# ATmega32M1 register map
Vendor: Atmel; File version: 1.0
CPU: other r0p0, little endian, no MPU, no FPU, 4 interrupt priority bits
Registers are 8-bit, read-write, reset 0x0 unless marked. A register's access mark holds for its fields unless they carry their own. Offsets are from the block's base; lines under a group give offsets from that group; [hi:lo] are bit positions; {n}, {i} and the like mark numbered series; 'fields as' and 'values as' point back to an identical list; <NAME> marks a mode.

## Memory map
0x00800000 FUSE size 0x3 — Fuses
0x00800000 LOCKBIT size 0x1 — Lockbits
0x00800023 PORTB size 0x3 — I/O Port
0x00800026 PORTC size 0x3 — I/O Port
0x00800029 PORTD size 0x3 — I/O Port
0x0080002C PORTE size 0x3 — I/O Port
0x00800035 TC0 blocks up to offset 0x3A — Timer/Counter, 8-bit
0x00800036 TC1 blocks up to offset 0x56 — Timer/Counter, 16-bit
0x00800039 CPU blocks up to offset 0x2E — CPU Registers
0x0080003B EXINT blocks up to offset 0x33 — External Interrupts
0x0080003F EEPROM size 0x4
0x0080004C SPI size 0x3 — Serial Peripheral Interface
0x00800050 AC blocks up to offset 0x48 — Analog Comparator
0x00800060 WDT size 0x1 — Watchdog Timer
0x00800075 ADC blocks up to offset 0xB — Analog-to-Digital Converter
0x00800090 DAC size 0x3 — Digital-to-Analog Converter
0x008000A0 PSC size 0x1D — Power Stage Controller
0x008000C8 LINUART size 0xB — Local Interconnect Network
0x008000D8 CAN size 0x23 — Controller Area Network

## Interrupts
0 RESET (CPU) — External Pin, Power-on Reset, Brown-out Reset, Watchdog Reset and JTAG AVR Reset
1 ANACOMP0 (CPU) — Analog Comparator 0
2 ANACOMP1 (CPU) — Analog Comparator 1
3 ANACOMP2 (CPU) — Analog Comparator 2
4 ANACOMP3 (CPU) — Analog Comparator 3
5 PSC_FAULT (CPU)
6 PSC_EC (CPU) — PSC End of Cycle
7 INT0 (CPU) — External Interrupt Request 0
8 INT1 (CPU) — External Interrupt Request 1
9 INT2 (CPU) — External Interrupt Request 2
10 INT3 (CPU) — External Interrupt Request 3
11 TIMER1_CAPT (CPU) — Timer/Counter1 Capture Event
12 TIMER1_COMPA (CPU) — Timer/Counter1 Compare Match A
13 TIMER1_COMPB (CPU) — Timer/Counter1 Compare Match B
14 TIMER1_OVF (CPU) — Timer1/Counter1 Overflow
15 TIMER0_COMPA (CPU) — Timer/Counter0 Compare Match A
16 TIMER0_COMPB (CPU) — Timer/Counter0 Compare Match B
17 TIMER0_OVF (CPU) — Timer/Counter0 Overflow
18 CAN_INT (CPU) — CAN MOB, Burst, General Errors
19 CAN_TOVF (CPU) — CAN Timer Overflow
20 LIN_TC (CPU) — LIN Transfer Complete
21 LIN_ERR (CPU) — LIN Error
22 PCINT0 (CPU) — Pin Change Interrupt Request 0
23 PCINT1 (CPU) — Pin Change Interrupt Request 1
24 PCINT2 (CPU) — Pin Change Interrupt Request 2
25 PCINT3 (CPU) — Pin Change Interrupt Request 3
26 SPI_STC (CPU) — SPI Serial Transfer Complete
27 ADC (CPU) — ADC Conversion Complete
28 WDT (CPU) — Watchdog Time-Out Interrupt
29 EE_READY (CPU) — EEPROM Ready
30 SPM_READY (CPU) — Store Program Memory Read

## AC — Analog Comparator
Base 0x00800050
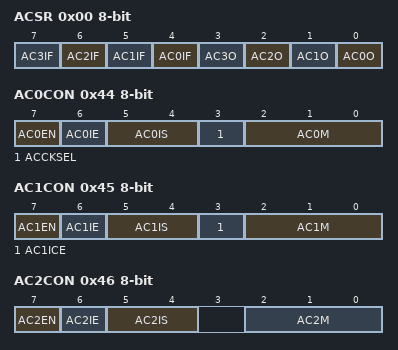
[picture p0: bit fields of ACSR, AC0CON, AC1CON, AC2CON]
0x00 ACSR — Analog Comparator Status Register (read-only for debugger)
  [n+4] AC{n}IF (n=0..3) — Analog Comparator {n} Interrupt Flag Bit
  [n] AC{n}O (n=0..3) — Analog Comparator {n} Output Bit
0x44 AC0CON — Analog Comparator 0 Control Register
  [7] AC0EN — Analog Comparator 0 Enable Bit
  [6] AC0IE — Analog Comparator 0 Interrupt Enable Bit
  [5:4] AC0IS — Analog Comparator 0 Interrupt Select Bits
  [3] ACCKSEL — Analog Comparator Clock Select
  [2:0] AC0M — Analog Comparator 0 Multiplexer Register
0x45 AC1CON — Analog Comparator 1 Control Register
  [7] AC1EN — Analog Comparator 1 Enable Bit
  [6] AC1IE — Analog Comparator 1 Interrupt Enable Bit
  [5:4] AC1IS — Analog Comparator 1 Interrupt Select Bit
    0=INTERRUPT_ON_TOGGLE; 2=INTERRUPT_ON_FALLING_EDGE; 3=INTERRUPT_ON_RISING_EDGE
  [3] AC1ICE — Analog Comparator 1 Interrupt Capture Enable Bit
  [2:0] AC1M — Analog Comparator 1 Multiplexer Register
0x46 AC2CON — Analog Comparator 2 Control Register
  [7] AC2EN — Analog Comparator 2 Enable Bit
  [6] AC2IE — Analog Comparator 2 Interrupt Enable Bit
  [5:4] AC2IS — Analog Comparator 2 Interrupt Select Bit
    values as AC1CON.AC1IS
  [2:0] AC2M — Analog Comparator 2 Multiplexer Register
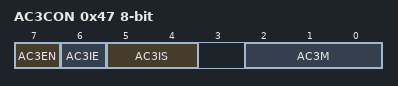
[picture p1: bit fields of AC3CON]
0x47 AC3CON — Analog Comparator 3 Control Register
  [7] AC3EN — Analog Comparator 3 Enable Bit
  [6] AC3IE — Analog Comparator 3 Interrupt Enable Bit
  [5:4] AC3IS — Analog Comparator 3 Interrupt Select Bit
    values as AC1CON.AC1IS
  [2:0] AC3M — Analog Comparator 3 Multiplexer Register
